AUTOSAR XML (schema 4-0-3)
standard types defined: UInt32, UInt8
package /AUTOSAR_Platform/DataConstrs
  range DC_UInt8: raw 0..255
package /PATAC/MSM/ComponentTypes
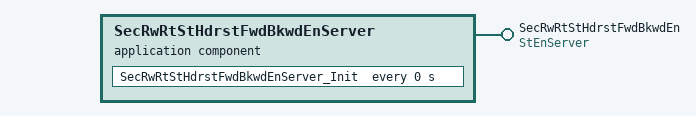
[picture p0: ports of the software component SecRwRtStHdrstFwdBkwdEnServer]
  application sw component type SecRwRtStHdrstFwdBkwdEnServer
    provide port SecRwRtStHdrstFwdBkwdEn: provided-com-specs=[{operation=Clear, queue-length=1}, {operation=Get, queue-length=1}, {operation=Set, queue-length=1}], provided-interface=StEnServer
    behavior SecRwRtStHdrstFwdBkwdEnServer_InternalBehavior
      operation invoked event OIT_SecRwRtStHdrstFwdBkwdEn_Clear_SecRwRtStHdrstFwdBkwdEn_Clear: start-on-event=SecRwRtStHdrstFwdBkwdEn_Clear, operation=SecRwRtStHdrstFwdBkwdEn.Clear
      operation invoked event OIT_SecRwRtStHdrstFwdBkwdEn_Get_SecRwRtStHdrstFwdBkwdEn_Get: start-on-event=SecRwRtStHdrstFwdBkwdEn_Get, operation=SecRwRtStHdrstFwdBkwdEn.Get
      operation invoked event OIT_SecRwRtStHdrstFwdBkwdEn_Set_SecRwRtStHdrstFwdBkwdEn_Set: start-on-event=SecRwRtStHdrstFwdBkwdEn_Set, operation=SecRwRtStHdrstFwdBkwdEn.Set
      timing event SecRwRtStHdrstFwdBkwdEnServer_InitEvent: start-on-event=SecRwRtStHdrstFwdBkwdEnServer_Init, period=0
      4 x runnable:
        SecRwRtStHdrstFwdBkwdEn_Clear
        SecRwRtStHdrstFwdBkwdEn_Get
        SecRwRtStHdrstFwdBkwdEn_Set
        SecRwRtStHdrstFwdBkwdEnServer_Init
  swc implementation SecRwRtStHdrstFwdBkwdEnServer_Implementation: behavior=SecRwRtStHdrstFwdBkwdEnServer_InternalBehavior
    code-descriptors:
      code Default: artifact-descriptors=autosar-engineering-object={short-label=Default, category=SWSRC}
package /PATAC/MSM/ModeAdjust/PortInterface
  client server interface StEnServer
    operation Clear
      arg data: type=UInt8, direction=IN, server-argument-impl-policy=USE-ARGUMENT-TYPE
    operation Get
      arg data: type=UInt32, direction=OUT, server-argument-impl-policy=USE-ARGUMENT-TYPE
    operation Set
      arg data: type=UInt8, direction=IN, server-argument-impl-policy=USE-ARGUMENT-TYPE
